# STM32L100xC register map
File version: 1.0
Registers are 32-bit, read-write, reset 0x0 unless marked. A register's access mark holds for its fields unless they carry their own. Offsets are from the block's base; [hi:lo] are bit positions; {n}, {i} and the like mark numbered series.

## RI — Routing Interface
Base 0x40007C04
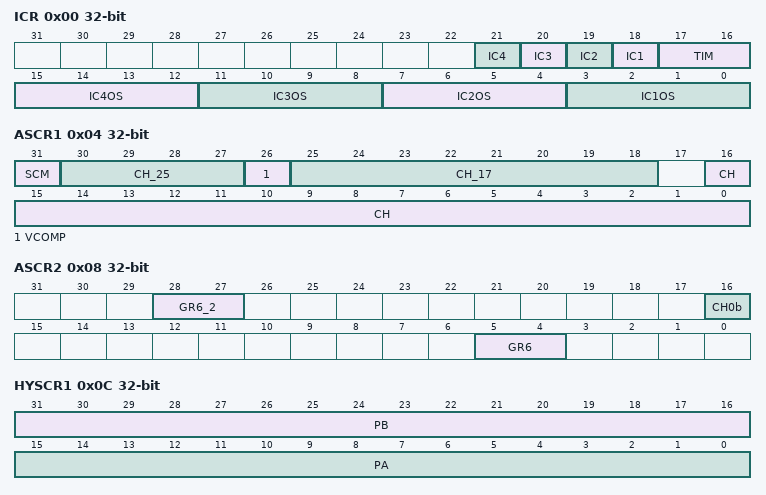
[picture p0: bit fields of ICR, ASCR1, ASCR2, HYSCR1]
0x00 ICR — RI input capture register
  [n+17] IC{n} (n=1..4) — Input capture {n}
  [17:16] TIM — TIM[3:0] bits (Timers select bits)
  [4n-1:4n-4] IC{n}OS (n=1..4) — IC{n}OS[3:0] bits (Input Capture {n} select bits)
0x04 ASCR1 — RI analog switches control register
  [31] SCM — I/O Switch control mode
  [30:27] CH_25 — AS_CH[25:18] & AS_CH[15:0] bits ( Analog switches selection bits)
  [26] VCOMP — ADC analog switch selection for internal node to COMP1
  [25:18] CH_17 — AS_CH[25:18] & AS_CH[15:0] bits ( Analog switches selection bits)
  [16:0] CH — AS_CH[25:18] & AS_CH[15:0] bits ( Analog switches selection bits)
0x08 ASCR2 — RI analog switch control register 2
  [28:27] GR6_2 — GR6 selection bits
  [16] CH0b — CH0b selection bit
  [5:4] GR6 — GR6 selection bits
0x0C HYSCR1 — RI hysteresis control register
  [31:16] PB — PB[15:0] Port B Hysteresis selection
  [15:0] PA — PA[15:0] Port A Hysteresis selection
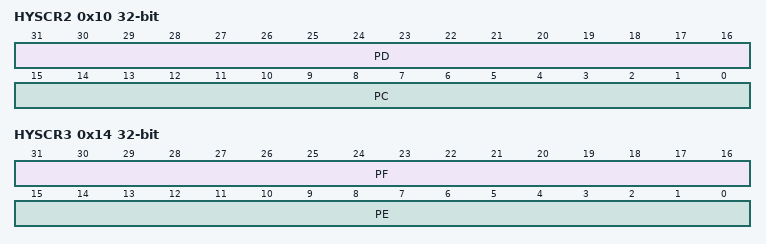
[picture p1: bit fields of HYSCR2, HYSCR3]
0x10 HYSCR2 — RI Hysteresis control register
  [31:16] PD — PD[15:0] Port D Hysteresis selection
  [15:0] PC — PC[15:0] Port C Hysteresis selection
0x14 HYSCR3 — RI Hysteresis control register
  [31:16] PF — PF[15:0] Port F Hysteresis selection
  [15:0] PE — PE[15:0] Port E Hysteresis selection
0x18 HYSCR4 — RI Hysteresis control register
  [15:0] PG — PG[15:0] Port G Hysteresis selection
0x1C ASMR1 — RI Analog switch mode register 1
  [15:0] PA — PA[15:0] Port A selection
0x20 CMR1 — RI Channel mask register 1
  [15:0] PA — PA[15:0] Port A selection
0x24 CICR1 — RI Channel Iden for capture register 1
  [15:0] PA — PA[15:0] Port A selection
0x28 ASMR2 — RI Analog switch mode register 2
  [15:0] PB — PB[15:0] Port B selection
0x2C CMR2 — RI Channel mask register 2
  [15:0] PB — PB[15:0] Port B selection
0x30 CICR2 — RI Channel Iden for capture register 2
  [15:0] PB — PB[15:0] Port B selection
0x34 ASMR3 — RI Analog switch mode register 3
  [15:0] PC — PC[15:0] Port C selection
0x38 CMR3 — RI Channel mask register 3
  [15:0] PC — PC[15:0] Port C selection
0x3C CICR3 — RI Channel Iden for capture register 3
  [15:0] PC — PC[15:0] Port C selection
0x40 ASMR4 — RI Analog switch mode register 4
  [15:0] PF — PF[15:0] Port F selection
0x44 CMR4 — RI Channel mask register 4
  [15:0] PF — PF[15:0] Port F selection
0x48 CICR4 — RI Channel Iden for capture register 4
  [15:0] PF — PF[15:0] Port F selection
0x4C ASMR5 — RI Analog switch mode register 5
  [15:0] PG — PG[15:0] Port G selection
0x50 CMR5 — RI Channel mask register 5
  [15:0] PG — PG[15:0] Port G selection
0x54 CICR5 — RI Channel Iden for capture register 5
  [15:0] PG — PG[15:0] Port G selection

## SYSCFG — SysTem Configuration
Base 0x40010000
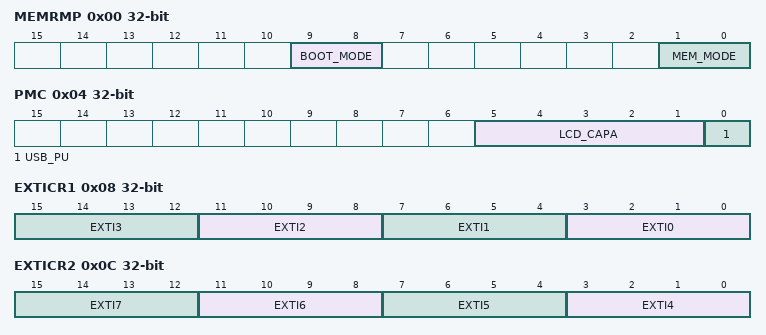
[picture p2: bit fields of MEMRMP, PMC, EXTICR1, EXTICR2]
0x00 MEMRMP — SYSCFG memory remap register
  [9:8] BOOT_MODE — Boot mode Config
    0=FLASH; 1=SYSTEMFLASH; 3=SRAM
  [1:0] MEM_MODE — SYSCFG_Memory Remap Config
    0=FLASH; 1=SYSTEMFLASH; 3=SRAM
0x04 PMC — SYSCFG peripheral mode configuration register
  [5:1] LCD_CAPA — LCD_CAPA decoupling capacitance connection
  [0] USB_PU — SYSCFG PMC
0x08 EXTICR1 — SYSCFG external interrupt configuration registers
  [4n+3:4n] EXTI{n} (n=0..3) — EXTI {n} configuration
0x0C EXTICR2 — SYSCFG external interrupt configuration registers
  [4n-13:4n-16] EXTI{n} (n=4..7) — EXTI {n} configuration
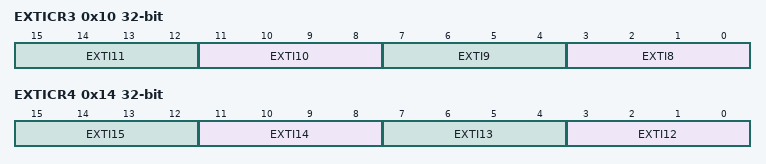
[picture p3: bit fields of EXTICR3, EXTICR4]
0x10 EXTICR3 — SYSCFG external interrupt configuration registers
  [4n-29:4n-32] EXTI{n} (n=8..11) — EXTI {n} configuration
0x14 EXTICR4 — SYSCFG external interrupt configuration registers
  [4n-45:4n-48] EXTI{n} (n=12..15) — EXTI {n} configuration

## EXTI — External Interrupt/Event Controller
Base 0x40010400
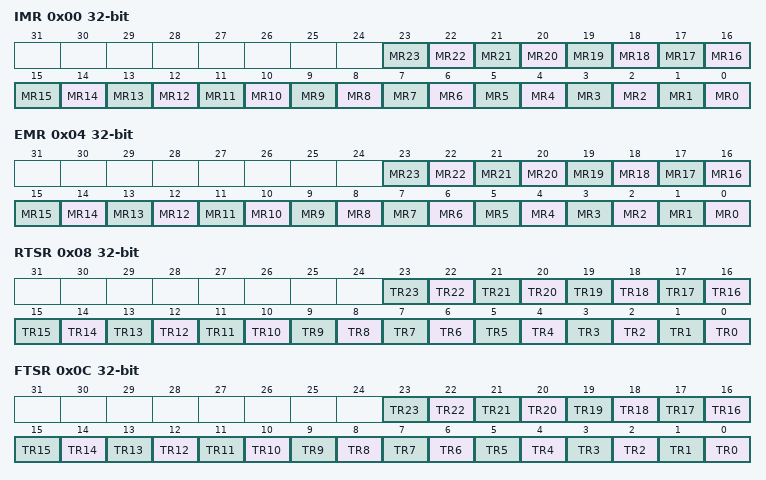
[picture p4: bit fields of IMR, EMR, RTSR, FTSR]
0x00 IMR — EXTI Interrupt mask register
  [n] MR{n} (n=0..23) — Interrupt Mask on line {n}
0x04 EMR — EXTI Event mask register
  [n] MR{n} (n=0..23) — Event Mask on line {n}
0x08 RTSR — EXTI Rising trigger selection register
  [n] TR{n} (n=0..23) — Rising trigger event configuration bit of line {n}
0x0C FTSR — EXTI Falling trigger selection register
  [n] TR{n} (n=0..23) — Falling trigger event configuration bit of line {n}
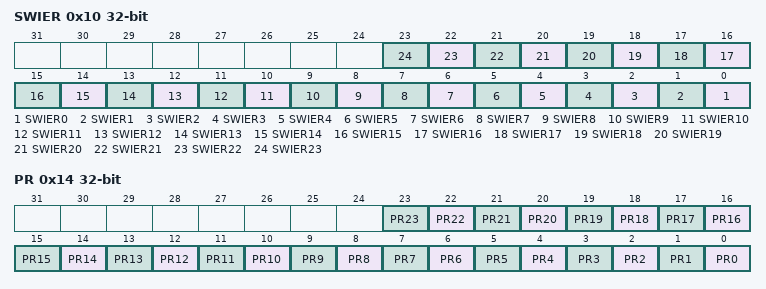
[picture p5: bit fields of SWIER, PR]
0x10 SWIER — EXTI Software interrupt event register
  [n] SWIER{n} (n=0..23) — Software Interrupt on line {n}
0x14 PR — EXTI Pending register
  [n] PR{n} (n=0..23) — Pending bit for line {n}
